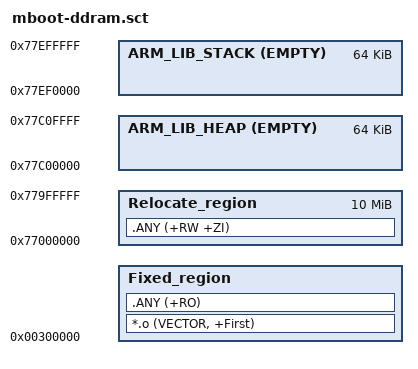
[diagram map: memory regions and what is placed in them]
;------------------------------------------------------------------------------
; *(STARTUP)
;------------------------------------------------------------------------------

Load_region 0x300000 0x10000 {    

    Fixed_region 0x300000 {
        *.o (VECTOR, +First)
        .ANY (+RO)
    }

	Relocate_region 0x77000000 0xA00000 {
        .ANY (+RW +ZI)
    }

    ScatterAssert((ImageLength(Fixed_region)) <  0xFFFF)
	
	ARM_LIB_HEAP 0x77C00000 EMPTY 0x10000 {
    }
    
    ARM_LIB_STACK 0x77F00000 EMPTY -0x10000 {
    }
}
